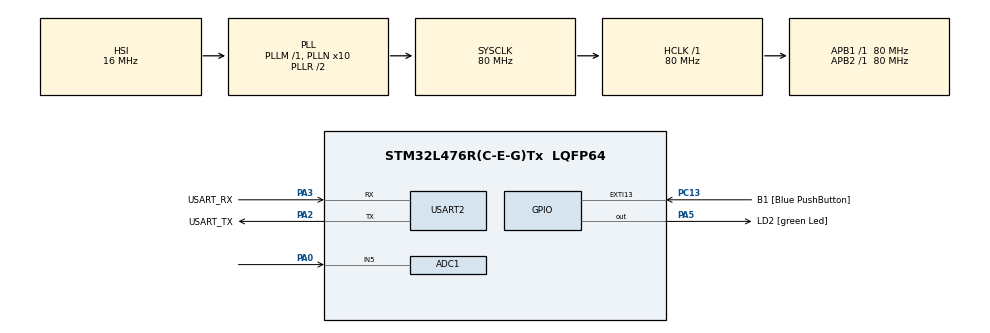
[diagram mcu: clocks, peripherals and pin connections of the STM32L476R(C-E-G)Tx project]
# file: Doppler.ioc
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ADC1.Channel-0\#ChannelRegularConversion=ADC_CHANNEL_5
ADC1.ContinuousConvMode=ENABLE
ADC1.DMAContinuousRequests=ENABLE
ADC1.NbrOfConversionFlag=1
ADC1.OffsetNumber-0\#ChannelRegularConversion=ADC_OFFSET_NONE
ADC1.Rank-0\#ChannelRegularConversion=1
ADC1.SamplingTime-0\#ChannelRegularConversion=ADC_SAMPLETIME_2CYCLES_5
ADC1.master=1
Dma.ADC1.0.Direction=DMA_PERIPH_TO_MEMORY
Dma.ADC1.0.Instance=DMA1_Channel1
Dma.ADC1.0.MemDataAlignment=DMA_MDATAALIGN_WORD
Dma.ADC1.0.MemInc=DMA_MINC_ENABLE
Dma.ADC1.0.Mode=DMA_CIRCULAR
Dma.ADC1.0.PeriphDataAlignment=DMA_PDATAALIGN_WORD
Dma.ADC1.0.PeriphInc=DMA_PINC_DISABLE
Dma.ADC1.0.Priority=DMA_PRIORITY_LOW
Dma.Request0=ADC1
Mcu.Family=STM32L4
Mcu.Name=STM32L476R(C-E-G)Tx
Mcu.Package=LQFP64
NVIC.DMA1_Channel1_IRQn=true\:0\:0\:false\:false\:true\:false\:true
NVIC.PriorityGroup=NVIC_PRIORITYGROUP_4
PA0.Signal=ADCx_IN5
PA13\ (JTMS-SWDIO).GPIO_Label=TMS
PA13\ (JTMS-SWDIO).Mode=Serial_Wire
PA13\ (JTMS-SWDIO).Signal=SYS_JTMS-SWDIO
PA14\ (JTCK-SWCLK).GPIO_Label=TCK
PA14\ (JTCK-SWCLK).Mode=Serial_Wire
PA14\ (JTCK-SWCLK).Signal=SYS_JTCK-SWCLK
PA2.GPIO_Label=USART_TX
PA2.GPIO_Mode=GPIO_MODE_AF_PP
PA2.GPIO_PuPd=GPIO_NOPULL
PA2.GPIO_Speed=GPIO_SPEED_FREQ_VERY_HIGH
PA2.Mode=Asynchronous
PA2.Signal=USART2_TX
PA3.GPIO_Label=USART_RX
PA3.GPIO_Mode=GPIO_MODE_AF_PP
PA3.GPIO_PuPd=GPIO_NOPULL
PA3.GPIO_Speed=GPIO_SPEED_FREQ_VERY_HIGH
PA3.Mode=Asynchronous
PA3.Signal=USART2_RX
PA5.GPIO_Label=LD2 [green Led]
PA5.GPIO_ModeDefaultOutputPP=GPIO_MODE_OUTPUT_PP
PA5.GPIO_PuPd=GPIO_NOPULL
PA5.GPIO_Speed=GPIO_SPEED_FREQ_LOW
PA5.Signal=GPIO_Output
PB3\ (JTDO-TRACESWO).GPIO_Label=SWO
PB3\ (JTDO-TRACESWO).Signal=SYS_JTDO-SWO
PC13.GPIO_Label=B1 [Blue PushButton]
PC13.GPIO_ModeDefaultEXTI=GPIO_MODE_IT_FALLING
PC13.GPIO_PuPd=GPIO_NOPULL
PC13.Signal=GPXTI13
PC14-OSC32_IN\ (PC14).Mode=LSE-External-Oscillator
PC14-OSC32_IN\ (PC14).Signal=RCC_OSC32_IN
PC15-OSC32_OUT\ (PC15).Mode=LSE-External-Oscillator
PC15-OSC32_OUT\ (PC15).Signal=RCC_OSC32_OUT
PH0-OSC_IN\ (PH0).Signal=RCC_OSC_IN
PH1-OSC_OUT\ (PH1).Signal=RCC_OSC_OUT
ProjectManager.HeapSize=0x200
ProjectManager.StackSize=0x400
ProjectManager.TargetToolchain=STM32CubeIDE
RCC.ADCFreq_Value=80000000
RCC.AHBFreq_Value=80000000
RCC.APB1Freq_Value=80000000
RCC.APB1TimFreq_Value=80000000
RCC.APB2Freq_Value=80000000
RCC.APB2TimFreq_Value=80000000
RCC.CortexFreq_Value=80000000
RCC.HCLKFreq_Value=80000000
RCC.HSE_VALUE=8000000
RCC.HSI_VALUE=16000000
RCC.MSI_VALUE=4000000
RCC.PLLN=10
RCC.PLLSAI1N=10
RCC.PLLSourceVirtual=RCC_PLLSOURCE_HSI
RCC.PREFETCH_ENABLE=1
RCC.SYSCLKFreq_VALUE=80000000
RCC.SYSCLKSource=RCC_SYSCLKSOURCE_PLLCLK
RCC.USBFreq_Value=80000000
RCC.VCOOutputFreq_Value=160000000
SH.ADCx_IN5.0=ADC1_IN5,IN5-Single-Ended
USART2.VirtualMode-Asynchronous=VM_ASYNC
board=NUCLEO-L476RG

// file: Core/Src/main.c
/* USER CODE BEGIN Header */
/**
 ******************************************************************************
 * @file           : main.c
 * @brief          : Main program body
 ******************************************************************************
 * @attention
 *
 * Copyright (c) 2023 STMicroelectronics.
 * All rights reserved.
 *
 * This software is licensed under terms that can be found in the LICENSE file
 * in the root directory of this software component.
 * If no LICENSE file comes with this software, it is provided AS-IS.
 *
 ******************************************************************************
 */
/* USER CODE END Header */
#include "main.h"

/* USER CODE BEGIN PD */

#define ADC_BUF_LEN 64
#define NChirp 64
#define ARM_MATH_CM4
#include "arm_math.h"
#include "arm_const_structs.h"
#include <stdio.h>

/* USER CODE END PD */

ADC_HandleTypeDef hadc1;
DMA_HandleTypeDef hdma_adc1;

UART_HandleTypeDef huart2;

/* USER CODE BEGIN PV */
volatile uint32_t adc_buf[ADC_BUF_LEN];
uint8_t Rx[1];

//
float fftIn[NChirp][ADC_BUF_LEN] = {
		{-2.5863e-07,0.00022521,-6.1129e-05,-0.00042889,-0.00063372,-0.00045172,0.00013064,0.0008364,0.00119,0.0008174,-0.00025078,-0.0014703,-0.002018,-0.0013331,0.00043194,0.0023155,0.0030704,0.0019489,-0.00066425,-0.0032882,-0.0041969,-0.0025598,0.00091116,0.0041832,0.0051644,0.0030204,-0.0011172,-0.004791,-0.0056927,-0.0031999,0.0012233,0.0049247,0.0056551,0.0030479,-0.001215,-0.0045326,-0.0050234,-0.0026021,0.0010731,0.0037453,0.0040073,0.0019829,-0.00084314,-0.0027672,-0.0028584,-0.0013587,0.00058805,0.0018357,0.001823,0.00083689,-0.00036713,-0.0010808,-0.0010406,-0.00045826,0.00020521,0.00056895,0.00052664,0.00022396,-9.8551e-05,-0.00026398,-0.0002363,-9.7033e-05,4.2643e-05,0.00010846},
		{-0.00011764,0.00017898,-0.00012513,-0.00047058,-0.00061149,-0.00035661,0.00025963,0.00091687,0.0011498,0.00063762,-0.00048411,-0.0016101,-0.0019384,-0.0010327,0.00081133,0.0025388,0.0029488,0.0014906,-0.0012138,-0.0035901,-0.0040229,-0.0019375,0.0016406,0.0045702,0.0049261,0.0022686,-0.0019787,-0.0052254,-0.0054236,-0.0023714,0.0021407,0.0053636,0.0053681,0.0022153,-0.0020766,-0.0049407,-0.004754,-0.0018683,0.0018137,0.0040752,0.0037649,0.0014075,-0.0014045,-0.0030077,-0.0026904,-0.00095257,0.0009798,0.0019907,0.0017101,0.00056679,-0.00060818,-0.0011744,-0.00097145,-0.00030637,0.00033652,0.00061764,0.00048979,0.00014542,-0.00016397,-0.0002872,-0.00021905,-6.1308e-05,7.1105e-05,0.00011804},
		{-0.00011015,0.00012903,-0.00018696,-0.00050252,-0.00057733,-0.00025347,0.00038414,0.00097933,0.00108,0.00044542,-0.00070618,-0.0017144,-0.0018181,-0.00070909,0.0011718,0.0026935,0.0027551,0.0010004,-0.0017455,-0.0038164,-0.0037456,-0.0012702,0.0023226,0.0048377,0.0045724,0.0014384,-0.0027793,-0.0055311,-0.0050245,-0.0014667,0.0029902,0.005658,0.0049447,0.001341,-0.0028798,-0.0051995,-0.0043644,-0.0010868,0.0024958,0.0042915,0.0034592,0.00078945,-0.0019363,-0.0031625,-0.0024403,-0.00050635,0.001338,0.0020875,0.001543,0.00028796,-0.00083399,-0.0012298,-0.00086914,-0.00014463,0.00045778,0.00064511,0.00043627,6.2856e-05,-0.00022415,-0.00029998,-0.00019372,-2.3393e-05,9.7596e-05,0.00012337},
		{-9.92e-05,7.6607e-05,-0.00024468,-0.00052442,-0.00053041,-0.00014508,0.00049937,0.0010169,0.00098916,0.00024342,-0.00091329,-0.0017758,-0.0016577,-0.00036211,0.0015022,0.0027943,0.002495,0.0004859,-0.0022199,-0.003941,-0.0033737,-0.0005738,0.0029427,0.0049939,0.004107,0.00059834,-0.0035146,-0.0056881,-0.0044787,-0.00054511,0.0037633,0.0058141,0.0043908,0.00041797,-0.0036197,-0.0053378,-0.0038509,-0.00028325,0.003115,0.0043794,0.0030248,0.00014219,-0.0023996,-0.0032272,-0.0021203,-4.6644e-05,0.0016624,0.0021263,0.0013323,-4.6784e-07,-0.0010256,-0.0012479,-0.00074569,2.0258e-05,0.00056583,0.00065152,0.00036944,-2.2081e-05,-0.00027703,-0.00030263,-0.00016118,1.4961e-05,0.00011988,0.00012391},
		{-8.4359e-05,2.23e-05,-0.00029649,-0.0005328,-0.00047058,-3.2248e-05,0.00060187,0.0010348,0.00087304,3.4527e-05,-0.0010975,-0.0018014,-0.0014553,-1.6385e-05,0.0017993,0.0028204,0.0021772,-3.6639e-05,-0.0026446,-0.0039727,-0.0029309,0.00013209,0.0034981,0.0050195,0.0035394,-0.00026208,-0.0041576,-0.005698,-0.0038353,0.00039655,0.0044361,0.0058185,0.0037253,-0.00050346,-0.0042427,-0.0053136,-0.0032384,0.00052693,0.003643,0.00435,0.00251,-0.0004978,-0.0028044,-0.0031967,-0.0017452,0.00040588,0.001932,0.0020939,0.0010796,-0.00029385,-0.0011875,-0.0012224,-0.00059551,0.00018867,0.00065455,0.00063775,0.00028787,-0.00010599,-0.00031898,-0.00029359,-0.00012337,5.313e-05,0.00013884,0.00011955},
		{-6.5572e-05,-3.1863e-05,-0.00034209,-0.00053086,-0.000402,7.9428e-05,0.00069079,0.0010252,0.00073898,-0.00017405,-0.001256,-0.0017828,-0.001222,0.00033221,0.0020497,0.0027875,0.0018099,-0.00056247,-0.0030129,-0.0039113,-0.0024137,0.00083755,0.0039664,0.0049229,0.002882,-0.001115,-0.00469,-0.0055654,-0.0030809,0.0013382,0.0049834,0.0056567,0.0029595,-0.0014233,-0.0047577,-0.0051481,-0.0025347,0.0013387,0.0040709,0.0042089,0.001939,-0.0011333,-0.0031284,-0.0030741,-0.0013213,0.00084896,0.00215,0.0020109,0.00079753,-0.00057447,-0.0013167,-0.0011666,-0.00042489,0.00034683,0.00072088,0.00060358,0.00019934,-0.0001875,-0.00035078,-0.00027612,-8.0629e-05,8.9955e-05,0.00015186,0.00011122},
		{-4.4987e-05,-8.5288e-05,-0.0003804,-0.00051694,-0.00032427,0.00019075,0.00076559,0.00099663,0.00058786,-0.00037903,-0.0013862,-0.0017235,-0.0009579,0.00067438,0.0022557,0.0026799,0.0014059,-0.001074,-0.0032934,-0.0037526,-0.0018382,0.0015231,0.0043342,0.0047063,0.0021646,-0.0019459,-0.005115,-0.0053009,-0.0022516,0.0022269,0.0054254,0.005367,0.0021134,-0.0022899,-0.0051627,-0.0048601,-0.0017598,0.0021051,0.004393,0.003936,0.001301,-0.0017265,-0.0033636,-0.0028611,-0.00085162,0.0012767,0.0022989,0.0018538,0.00048841,-0.0008426,-0.0014067,-0.0010709,-0.00024265,0.0004974,0.00076548,0.00054889,0.00010253,-0.00026251,-0.00037339,-0.00024879,-3.5161e-05,0.00012378,0.00016007,9.8307e-05},
		{-2.1865e-05,-0.00013698,-0.00040915,-0.0004919,-0.00023925,0.00029632,0.00082171,0.00094304,0.00042352,-0.00057465,-0.0014811,-0.001623,-0.00067552,0.00099553,0.0024036,0.0025186,0.00096431,-0.0015571,-0.0035087,-0.0034954,-0.0012211,0.0021654,0.004594,0.0043704,0.0013804,-0.0027198,-0.0054034,-0.0048994,-0.0013702,0.0030761,0.0057027,0.0049278,0.0012201,-0.0030982,-0.005399,-0.0044217,-0.00094545,0.0028024,0.0045966,0.0035692,0.00062846,-0.0022819,-0.0035016,-0.0025699,-0.00036219,0.0016607,0.0023817,0.0016455,0.00016443,-0.0010844,-0.001453,-0.00094278,-4.838e-05,0.00063287,0.00078912,0.00047523,4.2891e-07,-0.00033019,-0.00038034,-0.00021138,1.3107e-05,0.00015343,0.00016162,8.131e-05},
		{2.5976e-06,-0.00018533,-0.00042974,-0.00045539,-0.00014879,0.0003948,0.00085945,0.00086907,0.00024991,-0.00075517,-0.0015474,-0.0014898,-0.00037666,0.0012954,0.0024995,0.002291,0.00049326,-0.0019995,-0.0036346,-0.0031673,-0.00056768,0.0027579,0.0047405,0.0039255,0.00056304,-0.0034256,-0.0055488,-0.0043679,-0.00045365,0.0038299,0.0058449,0.0043541,0.00028945,-0.0038303,-0.0055208,-0.0038754,-0.00010485,0.0034312,0.0046734,0.0030948,-5.3815e-05,-0.0027742,-0.0035386,-0.0021995,0.00014857,0.0020009,0.0024009,0.0013922,-0.00016733,-0.0012943,-0.0014508,-0.00078229,0.00014514,0.0007494,0.00078475,0.00038693,-0.00010222,-0.00038643,-0.00037551,-0.0001665,6.1599e-05,0.00017796,0.00015889,6.1764e-05},
		{2.745e-05,-0.00022983,-0.0004403,-0.00040934,-5.5938e-05,0.00048496,0.00087769,0.00077467,7.1141e-05,-0.00091841,-0.0015737,-0.0013146,-6.8944e-05,0.0015629,0.0025373,0.0020112,2.1297e-05,-0.0023869,-0.0036732,-0.0027617,9.1685e-05,0.0032825,0.0047617,0.003381,-0.00027012,-0.0040506,-0.0055765,-0.0037289,0.00047327,0.0044867,0.0058374,0.0036755,-0.00064068,-0.0044545,-0.0054862,-0.0032368,0.00075557,0.0039776,0.0046115,0.0025405,-0.00075482,-0.0031797,-0.00348,-0.0017694,0.00064549,0.0022885,0.0023483,0.0010957,-0.00049918,-0.0014666,-0.0014088,-0.0005941,0.00033613,0.00084425,0.00075397,0.00028288,-0.00020324,-0.00043317,-0.0003578,-0.00011554,0.00010826,0.00019736,0.00014964,3.9021e-05},
		{5.1718e-05,-0.00026892,-0.00044147,-0.00035466,3.855e-05,0.00056291,0.00087732,0.00066379,-0.00010632,-0.0010619,-0.0015677,-0.001118,0.00023888,0.0017963,0.0025132,0.0016842,-0.00045753,-0.0027306,-0.0036219,-0.0022871,0.00074457,0.0037252,0.0046783,0.0027627,-0.0010879,-0.0045639,-0.0054402,-0.002997,0.0013832,0.005031,0.0056805,0.0028939,-0.0015707,-0.0049696,-0.0052956,-0.00249,0.0015767,0.0044137,0.0044329,0.001908,-0.0014224,-0.0035093,-0.0033213,-0.0012861,0.0011363,0.0025033,0.0022229,0.00075869,-0.00081677,-0.0015982,-0.0013229,-0.00038806,0.00052174,0.00091149,0.00070155,0.00016921,-0.00029905,-0.00046394,-0.00032895,-5.8921e-05,0.00015162,0.00020978,0.00013485,1.3939e-05},
		{7.5069e-05,-0.00030207,-0.00043396,-0.00029179,0.00013147,0.00063024,0.0008564,0.00053916,-0.00028364,-0.0011792,-0.0015209,-0.00089354,0.00054236,0.0019839,0.0024278,0.0013208,-0.0009202,-0.0030034,-0.0034791,-0.0017489,0.0013959,0.0040818,0.0044769,0.0020763,-0.0018779,-0.0049787,-0.0051686,-0.002184,0.0022759,0.0054483,0.0053599,0.0020355,-0.0024522,-0.0053551,-0.004974,-0.0016842,0.002371,0.0047338,0.0041289,0.0012223,-0.0020515,-0.0037393,-0.0030662,-0.00075935,0.0015968,0.0026486,0.0020278,0.00040187,-0.0011099,-0.001681,-0.0011996,-0.00017203,0.0006919,0.00095168,0.00062372,4.9869e-05,-0.0003863,-0.00048115,-0.00028704,1.7882e-07,0.00019256,0.00021644,0.00011529,-1.2205e-05},
		{9.6483e-05,-0.00032901,-0.00041589,-0.00022376,0.0002218,0.00068225,0.00081756,0.00040243,-0.00045272,-0.0012705,-0.0014437,-0.00064855,0.00083013,0.0021292,0.0022884,0.00092671,-0.0013606,-0.0031989,-0.003262,-0.0011806,0.0019936,0.0043238,0.0041672,0.001328,-0.0026201,-0.0052592,-0.0047807,-0.0013137,0.003097,0.0057367,0.0049066,0.0011219,-0.0032848,-0.0056054,-0.0045098,-0.00082013,0.0031132,0.0049182,0.0037118,0.00049064,-0.0026448,-0.0038676,-0.00272,-0.00021152,0.0020126,0.0027281,0.0017836,2.91e-05,-0.0013789,-0.0017167,-0.0010318,5.9507e-05,0.0008431,0.00096625,0.00052681,-7.5191e-05,-0.00046325,-0.00048322,-0.00023422,6.0965e-05,0.00022733,0.00021433,9.0781e-05,-3.8583e-05},
		{0.00011496,-0.00034883,-0.00038855,-0.00014905,0.00030676,0.00071984,0.00075899,0.00025588,-0.0006137,-0.0013321,-0.0013316,-0.00038699,0.0011003,0.0022238,0.0020972,0.00051196,-0.0017654,-0.0033271,-0.0029634,-0.00058109,0.0025553,0.0044681,0.0037519,0.00054944,-0.0033137,-0.0054078,-0.0042454,-0.00042156,0.0038484,0.0058599,0.0043297,0.00019292,-0.0040113,-0.0056931,-0.0039331,5.5395e-05,0.0037571,0.0049737,0.003191,-0.00024307,-0.003161,-0.0038874,-0.0023026,0.00034388,0.0023824,0.0027198,0.0014769,-0.00035322,-0.0016047,-0.0016989,-0.00083034,0.00028706,0.00097102,0.00094723,0.00041008,-0.00019995,-0.0005265,-0.00046987,-0.00017457,0.00012129,0.00025537,0.00020532,6.1767e-05,-6.4333e-05},
		{0.00013033,-0.00036039,-0.00035343,-7.1841e-05,0.00038439,0.00074062,0.0006841,0.00010409,-0.0007596,-0.0013654,-0.0011883,-0.00011632,0.0013427,0.0022647,0.0018543,7.9275e-05,-0.0021353,-0.0033759,-0.0025899,3.0714e-05,0.003057,0.0045077,0.0032449,-0.00023792,-0.0039112,-0.0054143,-0.0036371,0.00050191,0.0044996,0.0058382,0.0036417,-0.00076267,-0.0046447,-0.0056439,-0.0032577,0.00094633,0.0043175,0.004888,0.0025757,-0.00098712,-0.0035798,-0.0038009,-0.0018185,0.00089812,0.0026777,0.002636,0.0011246,-0.00072798,-0.0017901,-0.0016326,-0.00060296,0.00051025,0.0010735,0.00089914,0.00027884,-0.00032433,-0.00057426,-0.00043976,-0.00010712,0.00017967,0.00027552,0.00019051,3.0763e-05,-8.9457e-05},
		{0.00014164,-0.00036448,-0.00031035,5.7175e-06,0.00045445,0.00074318,0.00059448,-4.9037e-05,-0.00088692,-0.0013662,-0.0010222,0.00015345,0.0015559,0.0022513,0.0015704,-0.00035514,-0.0024528,-0.0033369,-0.0021584,0.00064311,0.0034662,0.0044318,0.0026559,-0.0010146,-0.0044067,-0.0052929,-0.0029168,0.0014077,0.0050349,0.0056695,0.0028465,-0.0017028,-0.0051633,-0.0054496,-0.0024685,0.0018022,0.0047449,0.0046796,0.0018951,-0.0017007,-0.0039205,-0.0035947,-0.0012718,0.0014426,0.0028988,0.0024752,0.00073032,-0.001082,-0.0019216,-0.0015163,-0.00035949,0.0007257,0.0011405,0.00082399,0.00013755,-0.00043574,-0.00060655,-0.00039608,-3.4306e-05,0.00023383,0.00028731,0.0001674,-2.8903e-06,-0.00011196},
		{0.00014879,-0.00036059,-0.00026135,8.4097e-05,0.00051374,0.00073114,0.00049131,-0.00020229,-0.00099468,-0.0013355,-0.00082588,0.00042131,0.001731,0.0021881,0.0012501,-0.00076687,-0.0027079,-0.00322,-0.0016737,0.0012444,0.003807,0.0042532,0.0020102,-0.0017794,-0.0048061,-0.0050384,-0.0021207,0.0022643,0.0054497,0.00537,0.0019873,-0.0025811,-0.0055472,-0.0050893,-0.0016381,0.0026279,0.0050558,0.0043447,0.001156,-0.0023795,-0.0041463,-0.0033015,-0.00068255,0.0019353,0.0030403,0.0022402,0.0003175,-0.0014086,-0.0020063,-0.0013505,-9.3756e-05,0.0009194,0.0011779,0.00072199,-1.4095e-05,-0.00053761,-0.00062046,-0.00033803,4.2828e-05,0.00028223,0.00029065,0.00013852,-3.8372e-05,-0.00013227},
		{0.00015106,-0.00034863,-0.00020558,0.00015983,0.00056033,0.00070357,0.00037806,-0.00034948,-0.0010798,-0.0012748,-0.00061717,0.00067853,0.001865,0.002074,0.00089754,-0.001172,-0.0029003,-0.0030279,-0.0011483,0.0018172,0.0040493,0.003966,0.0013007,-0.0024963,-0.0050737,-0.0046615,-0.0012849,0.0030874,0.0057107,0.0049023,0.0010732,-0.0034105,-0.0057755,-0.0046166,-0.00074281,0.0033805,0.005235,0.0038848,0.00036691,-0.0029961,-0.0042624,-0.0029064,-7.6104e-05,0.0023851,0.0031029,0.0019398,-0.00011399,-0.0017045,-0.0020265,-0.001143,0.00017573,0.0010928,0.0011823,0.00059285,-0.00016444,-0.00062631,-0.00061336,-0.00026741,0.00012079,0.00032223,0.00028404,0.00010362,-7.2786e-05,-0.00014881},
		{0.00014801,-0.00032887,-0.00014595,0.00023233,0.00059559,0.00065787,0.00025516,-0.00048898,-0.0011398,-0.0011831,-0.00039456,0.00091972,0.0019602,0.0019066,0.00052666,-0.0015492,-0.0030251,-0.0027617,-0.00059861,0.002338,0.0041974,0.0035779,0.0005674,-0.0031475,-0.0052293,-0.0041675,-0.00039604,0.0038186,0.0058491,0.0043186,0.00012632,-0.0041566,-0.0058649,-0.0040054,0.00017689,0.0040464,0.005281,0.0033187,-0.00041822,-0.003543,-0.0042611,-0.0024355,0.00054784,0.0027741,0.0030819,0.0015799,-0.00054388,-0.0019582,-0.0019886,-0.00090121,0.00044776,0.0012338,0.0011467,0.00044635,-0.00031663,-0.00070027,-0.00058921,-0.00018801,0.00019704,0.00035487,0.00026843,6.4099e-05,-0.00010672,-0.00016079},
		{0.00014078,-0.00030262,-8.3354e-05,0.00029917,0.00061724,0.00060054,0.00012704,-0.00061723,-0.0011736,-0.0010677,-0.00015653,0.0011397,0.0020051,0.001699,0.00014304,-0.0018883,-0.0030788,-0.0024333,-3.2595e-05,0.0028036,0.0042387,0.0031062,-0.00018362,-0.0037252,-0.0052436,-0.0035562,0.0004956,0.004459,0.0058261,0.0036243,-0.00082849,-0.0047846,-0.005798,-0.0032916,0.0010984,0.0046034,0.0051812,0.0026585,-0.0012111,-0.003987,-0.0041446,-0.0018851,0.001158,0.0030964,0.0029704,0.0011716,-0.00096232,-0.0021571,-0.0018978,-0.00062579,0.00071052,0.0013432,0.0010804,0.00028283,-0.0004632,-0.00075126,-0.0005464,-9.7915e-05,0.00026997,0.00037675,0.0002444,2.1444e-05,-0.00013913,-0.00016859},
		{0.00012807,-0.00026988,-1.8875e-05,0.00035992,0.00062563,0.00052898,-3.0763e-06,-0.00073036,-0.0011805,-0.00092472,7.7966e-05,0.0013295,0.0020049,0.0014563,-0.00024551,-0.0021805,-0.0030579,-0.0020455,0.00052894,0.0032011,0.0041779,0.0025579,-0.00093485,-0.0042208,-0.0051403,-0.0028645,0.0013836,0.004998,0.0056602,0.0028415,-0.0017699,-0.0053052,-0.0055848,-0.0024927,0.0019956,0.00506,0.0049461,0.0019131,-0.0019798,-0.0043371,-0.0039174,-0.0012813,0.0017378,0.0033323,0.0027644,0.00072467,-0.0013721,-0.0022941,-0.0017461,-0.00032949,0.00095898,0.0014174,0.00097752,0.00010526,-0.00059937,-0.00078307,-0.00048333,-4.0204e-06,0.00033477,0.00038767,0.00021131,-2.4077e-05,-0.00016778,-0.00017124},
		{0.0001111,-0.00023084,4.6073e-05,0.00041156,0.00061929,0.00044419,-0.0001335,-0.0008277,-0.0011618,-0.00076547,0.00031309,0.0014936,0.00196,0.001174,-0.00062499,-0.002421,-0.0029609,-0.0016079,0.0010824,0.0035225,0.0040166,0.0019526,-0.0016561,-0.0046067,-0.004893,-0.0020976,0.0022313,0.0053971,0.0053478,0.0019714,-0.0026617,-0.005683,-0.0052212,-0.0016095,0.0028446,0.0053845,0.0045796,0.0011224,-0.0026942,-0.0045684,-0.0035755,-0.0006221,0.0022911,0.0034759,0.0024897,0.00024684,-0.0017405,-0.0023673,-0.0015405,-1.4915e-05,0.0011842,0.0014484,0.00084497,-8.0398e-05,-0.00072185,-0.00079261,-0.00040757,9.2938e-05,0.00039398,0.00038719,0.00017057,-6.9876e-05,-0.00019311,-0.0001686},
		{8.9581e-05,-0.00018727,0.00010947,0.00045468,0.00059994,0.0003515,-0.00025935,-0.00090723,-0.0011161,-0.00058528,0.00053965,0.0016228,0.0018655,0.0008658,-0.00099241,-0.0026079,-0.0027961,-0.001134,0.0016113,0.0037626,0.0037644,0.0012925,-0.0023368,-0.004877,-0.0045388,-0.0012759,0.0030237,0.0056709,0.0048882,0.0010544,-0.003494,-0.0059236,-0.0047258,-0.00068242,0.0036102,0.005553,0.0040742,0.00028364,-0.0033503,-0.0046832,-0.0031329,4.5313e-05,0.0027756,0.0035234,0.0021424,-0.00024605,-0.0020705,-0.0023831,-0.0012867,0.00030479,0.0013821,0.0014417,0.00068243,-0.0002673,-0.00082683,-0.00077734,-0.00031366,0.00019038,0.00044204,0.00037475,0.00012269,-0.00011642,-0.00021277,-0.00016082},
		{6.4215e-05,-0.00013954,0.00017033,0.00048795,0.00056735,0.00025008,-0.00037976,-0.00096496,-0.0010473,-0.00039349,0.000753,0.001713,0.0017297,0.00053597,-0.0013319,-0.0027332,-0.0025689,-0.0006325,0.0021039,0.0039059,0.0034144,0.00059747,-0.0029668,-0.0050285,-0.0040555,-0.00041658,0.0037441,0.0057971,0.0043129,0.00010366,-0.0042446,-0.006009,-0.0041027,0.00025775,0.0043044,0.0055859,0.003464,-0.00056934,-0.0039281,-0.0046644,-0.0025976,0.00072593,0.0031944,0.0034775,0.0017173,-0.00073972,-0.0023452,-0.0023251,-0.00099779,0.00061969,0.0015427,0.0013899,0.00049906,-0.00045198,-0.00091112,-0.00074094,-0.00020934,0.00028742,0.00048065,0.0003511,6.9434e-05,-0.00016099,-0.00022738,-0.00014761},
		{3.5558e-05,-8.871e-05,0.0002274,0.00050953,0.00052268,0.00014353,-0.00049311,-0.00099996,-0.0009528,-0.00019245,0.00095081,0.0017614,0.0015557,0.00020153,-0.0016413,-0.002787,-0.0022766,-0.00011215,0.0025405,0.0039651,0.0029772,-0.00011189,-0.0035246,-0.0050515,-0.0034823,0.00044666,0.0043807,0.0057909,0.0036297,-0.0008509,-0.0048874,-0.0059464,-0.003366,0.0012081,0.0048938,0.0054664,0.0027489,-0.0014094,-0.0043901,-0.0045172,-0.0019862,0.0014004,0.0035372,0.003338,0.0012458,-0.0012212,-0.0025604,-0.0022055,-0.0006674,0.00092877,0.0016628,0.0012992,0.00029448,-0.00062754,-0.00096626,-0.00068066,-9.5352e-05,0.00037733,0.00050393,0.00031555,1.2604e-05,-0.00020161,-0.0002353,-0.00012957},
		{4.7465e-06,-3.6672e-05,0.00027958,0.00052043,0.00046538,3.515e-05,-0.0005924,-0.001011,-0.00083617,1.2379e-05,0.0011266,0.0017739,0.0013434,-0.00014616,-0.0019148,-0.002777,-0.0019298,0.00040568,0.0029249,0.0039147,0.0024707,-0.00081284,-0.0039924,-0.0049589,-0.0028153,0.0012987,0.004919,0.0056176,0.0028436,-0.0017868,-0.0054147,-0.0057191,-0.0025326,0.0021331,0.0053568,0.0052159,0.0019768,-0.0022165,-0.0047619,-0.0042621,-0.0013165,0.0020427,0.0037937,0.0031052,0.00073287,-0.001673,-0.0027076,-0.0020174,-0.00031828,0.0012157,0.0017387,0.0011683,7.8854e-05,-0.00079143,-0.00099995,-0.00059911,2.4603e-05,0.00045952,0.00051517,0.00027094,-4.7688e-05,-0.00023899,-0.00023763,-0.00010672},
		{-2.7589e-05,1.6694e-05,0.00032533,0.00051975,0.00039852,-7.5884e-05,-0.00068012,-0.0010048,-0.00070074,0.00021386,0.001273,0.0017388,0.0011024,-0.00048477,-0.0021402,-0.0027057,-0.0015436,0.00091788,0.0032292,0.0037806,0.0019098,-0.0015004,-0.0043719,-0.0047366,-0.0020839,0.0021338,0.0053123,0.0053204,0.0019842,-0.0026872,-0.0057933,-0.0053525,-0.0016406,0.0030014,0.0056828,0.0048087,0.0011238,-0.0029882,-0.0049861,-0.0038685,-0.00060046,0.0026481,0.0039394,0.0027762,0.00019131,-0.0020925,-0.0027885,-0.0017737,5.5129e-05,0.0014773,0.0017653,0.0010002,-0.00015138,-0.00093644,-0.0010038,-0.00049717,0.00014806,0.00053183,0.00051068,0.00021572,-0.00010858,-0.00026983,-0.00023237,-7.9635e-05},
		{-6.0453e-05,6.9346e-05,0.0003643,0.00050799,0.00032341,-0.000183,-0.00075193,-0.00097205,-0.00055072,0.00041619,0.0013917,0.0016666,0.00083362,-0.00081516,-0.0023154,-0.0025719,-0.0011098,0.0014104,0.0034581,0.0035502,0.0012953,-0.002153,-0.0046385,-0.004403,-0.0012913,0.0029277,0.005591,0.0048835,0.0010815,-0.0035184,-0.0060329,-0.0048406,-0.00068729,0.0038086,0.0058527,0.0042869,0.0002307,-0.0036803,-0.0051024,-0.0033809,0.00014591,0.0031779,0.0039856,0.0023718,-0.0003667,-0.0024592,-0.0027887,-0.0014705,0.00042942,0.0017028,0.0017484,0.00079964,-0.0003767,-0.0010624,-0.00098143,-0.0003773,0.00027228,0.00059223,0.00049169,0.00015117,-0.00016867,-0.00029575,-0.00021969,-4.9146e-05},
		{-9.3183e-05,0.00012061,0.00039408,0.00048498,0.00024067,-0.0002873,-0.00080706,-0.00091774,-0.00039044,0.00060286,0.0014809,0.0015569,0.00054853,-0.0011255,-0.0024384,-0.0023746,-0.00065445,0.0018633,0.00361,0.0032392,0.00063813,-0.0027507,-0.0047946,-0.0039528,-0.00046121,0.0036313,0.0057189,0.0043093,0.00011831,-0.0042839,-0.0061268,-0.0041987,0.00029684,0.0045253,0.0058885,0.0036312,-0.00066288,-0.0042845,-0.0050737,-0.0027935,0.00089207,0.0036441,0.0039178,0.0018903,-0.00093023,-0.0027693,-0.0027134,-0.0011204,0.00080722,0.0018879,0.0016794,0.00057444,-0.00060133,-0.0011572,-0.00092951,-0.00024331,0.00039438,0.0006341,0.00045711,8.0529e-05,-0.00022639,-0.00031251,-0.00020053,-1.5819e-05},
		{-0.00012533,0.00016881,0.00041602,0.000451,0.00015255,-0.00038469,-0.0008436,-0.00084195,-0.00021768,0.00078075,0.0015326,0.0014134,0.00024877,-0.0014072,-0.0025031,-0.0021196,-0.00018778,0.0022781,0.003672,0.0028439,-2.0947e-05,-0.0032882,-0.004834,-0.0034156,0.0003772,0.0042557,0.0057139,0.0036281,-0.0008316,-0.0049376,-0.0060669,-0.0034518,0.0012737,0.0051214,0.0057569,0.0028913,-0.0015529,-0.0047836,-0.0049123,-0.002126,0.0016243,0.0039973,0.0037501,0.0013624,-0.001469,-0.0030066,-0.0025558,-0.00073134,0.0011637,0.0020253,0.0015613,0.00032112,-0.00081268,-0.0012239,-0.00084819,-9.862e-05,0.00050527,0.00066375,0.00040958,5.2009e-06,-0.00027944,-0.00032294,-0.00017514,1.9299e-05},
		{-0.0001549,0.00021322,0.0004288,0.00040778,6.2408e-05,-0.00047175,-0.00086144,-0.00075023,-4.4789e-05,0.00093773,0.0015509,0.001235,-5.5491e-05,-0.0016596,-0.0025122,-0.0018196,0.00028916,0.0026374,0.0036439,0.0023862,-0.00067742,-0.0037489,-0.0047585,-0.0027847,0.0012033,0.0047739,0.0055617,0.0028723,-0.001765,-0.0054576,-0.0058352,-0.0026066,0.0022206,0.0056037,0.0054821,0.0020645,-0.002429,-0.0051651,-0.0046187,-0.0013893,0.0023311,0.0042719,0.0034728,0.00076895,-0.0019816,-0.0031657,-0.0023367,-0.0003212,0.0014976,0.0021109,0.0013973,5.6596e-05,-0.0010116,-0.0012586,-0.00074356,5.3547e-05,0.00060786,0.00067435,0.00034856,-7.2294e-05,-0.00032728,-0.00032355,-0.00014342,5.5647e-05},
		{-0.00018082,0.00025263,0.00043215,0.00035473,-3.0153e-05,-0.00054964,-0.00085932,-0.00064072,0.00013367,0.0010727,0.0015349,0.0010302,-0.0003579,-0.0018695,-0.0024605,-0.0014733,0.00075358,0.0029312,0.0035362,0.0018626,-0.0013251,-0.0041107,-0.004559,-0.0020781,0.0020117,0.0051828,0.0052714,0.0020192,-0.0026737,-0.0058625,-0.0054689,-0.0016882,0.0031278,0.0059416,0.0050651,0.0011656,-0.0032299,-0.0054088,-0.0041962,-0.00061141,0.0029856,0.0044246,0.0031077,0.00016203,-0.0024497,-0.0032487,-0.002043,0.00011428,0.0018045,0.0021366,0.0011947,-0.0002174,-0.0011803,-0.0012614,-0.00061405,0.00020617,0.00069598,0.00066564,0.00027576,-0.00015056,-0.00036731,-0.00031475,-0.00010644,9.1639e-05},
		{-0.00020396,0.00028735,0.00042615,0.00029407,-0.00012182,-0.0006163,-0.00083881,-0.00051684,0.00030486,0.0011837,0.0014813,0.0008012,-0.00065045,-0.0020399,-0.0023451,-0.0010924,0.0012042,0.0031525,0.0033356,0.0013041,-0.001947,-0.0043829,-0.004251,-0.0013273,0.0027768,0.0054615,0.004855,0.0011138,-0.0035063,-0.0061064,-0.0049584,-0.0007204,0.0039497,0.006134,0.0045199,0.00022685,-0.0039631,-0.0055252,-0.0036616,0.00020023,0.0035698,0.0044615,0.002654,-0.00046761,-0.00287,-0.0032392,-0.0016862,0.00055229,0.0020621,0.0021052,0.00094919,-0.00049321,-0.0013316,-0.0012259,-0.00046229,0.00036362,0.0007707,0.0006395,0.00019404,-0.00022998,-0.00039912,-0.00029736,-6.564e-05,0.00012681},
		{-0.00022229,0.00031498,0.00041071,0.00022754,-0.00020921,-0.00066788,-0.00079905,-0.00037983,0.00047304,0.0012676,0.0013953,0.00055184,-0.00093361,-0.0021606,-0.0021819,-0.00068605,0.0016267,0.0033065,0.0030623,0.00070289,-0.0025167,-0.0045398,-0.0038381,-0.00053805,0.0034669,0.0055923,0.0043093,0.00017934,-0.0042647,-0.0061987,-0.0043142,0.00028329,0.0046913,0.0061649,0.0038339,-0.00072097,-0.0046082,-0.0054826,-0.0030342,0.0010294,0.0040734,0.0043907,0.0021092,-0.0011004,-0.003214,-0.003146,-0.001283,0.00098928,0.0022742,0.0020148,0.00067475,-0.00076271,-0.0014473,-0.0011612,-0.00029602,0.0005142,0.00082509,0.00059369,0.00010087,-0.00030428,-0.00042122,-0.00027113,-2.0427e-05,0.00015979},
		{-0.00023461,0.00033594,0.00038671,0.00015654,-0.00029283,-0.00070364,-0.00074157,-0.00023659,0.00062818,0.0013193,0.0012789,0.00029324,-0.0011895,-0.0022308,-0.0019642,-0.00026097,0.0020123,0.0033811,0.0027072,8.6224e-05,-0.0030346,-0.0045883,-0.0033327,0.00026879,0.0040831,0.0056056,0.0036545,-0.00076012,-0.0049204,-0.006136,-0.0035426,0.0012735,0.0053184,0.006031,0.003059,-0.001669,-0.0051473,-0.0053206,-0.0023067,0.0018184,0.0044783,0.0041935,0.0015084,-0.0017031,-0.0034756,-0.0029631,-0.00083278,0.0014031,0.0024299,0.0018746,0.00037265,-0.0010182,-0.0015233,-0.0010565,-0.00011386,0.00065361,0.0008568,0.00053115,3.6384e-06,-0.00037371,-0.00043284,-0.00023734,2.6071e-05,0.00018984},
		{-0.00024202,0.0003496,0.00035342,8.1709e-05,-0.00036958,-0.00072461,-0.00066758,-8.8409e-05,0.00076709,0.0013464,0.001128,2.5349e-05,-0.0014181,-0.002251,-0.0017052,0.00016694,0.0023498,0.0033694,0.0022923,-0.00053294,-0.0034724,-0.0045376,-0.0027394,0.0010671,0.0046003,0.0054721,0.0028954,-0.0016993,-0.0054504,-0.0059275,-0.0027065,0.0022514,0.0058087,0.0057606,0.0021815,-0.0025856,-0.0055523,-0.005001,-0.0014969,0.0025808,0.0047558,0.0038877,0.00085349,-0.0022901,-0.0036563,-0.0027062,-0.00035269,0.0017936,0.0025205,0.0016789,5.2022e-05,-0.0012564,-0.0015637,-0.00092547,7.504e-05,0.00078061,0.00086922,0.00045354,-9.7849e-05,-0.00043514,-0.00043289,-0.00019442,7.5241e-05,0.00021632},
		{-0.00024246,0.00035564,0.00031277,5.3733e-06,-0.00043749,-0.0007291,-0.00057958,6.2998e-05,0.00089055,0.0013421,0.00095633,-0.00024239,-0.0016153,-0.0022154,-0.0014026,0.00059054,0.002627,0.0032825,0.0018256,-0.0011443,-0.0038277,-0.0043674,-0.0020843,0.0018505,0.0050018,0.0052041,0.0020734,-0.0025873,-0.0058658,-0.0055528,-0.0017649,0.0031843,0.0061553,0.0053185,0.0012404,-0.0034391,-0.0058121,-0.0045549,-0.00065888,0.0032953,0.0049334,0.0034709,0.00015883,-0.0028201,-0.003745,-0.0023649,0.00015114,0.0021509,0.0025534,0.0014289,-0.00027721,-0.0014622,-0.0015642,-0.00076495,0.00026926,0.00089291,0.00085618,0.0003582,-0.00019933,-0.00048675,-0.00042144,-0.00014543,0.00012304,0.0002378},
		{-0.00023695,0.00035401,0.00026469,-7.1135e-05,-0.00049705,-0.00071791,-0.00047806,0.00021273,0.00099318,0.0013045,0.00076021,-0.00050498,-0.0017772,-0.0021315,-0.0010633,0.0010065,0.0028444,0.0031167,0.0013072,-0.0017248,-0.0041,-0.004091,-0.0013703,0.0025947,0.005291,0.0048037,0.0011987,-0.0034286,-0.0061258,-0.0050551,-0.00078858,0.0040334,0.0063656,0.0047535,0.00026289,-0.0042222,-0.0059369,-0.0039787,0.00021898,0.0039362,0.0049668,0.0029658,-0.00054353,-0.0032821,-0.0037331,-0.0019503,0.00065976,0.0024546,0.0025142,0.0011395,-0.00060377,-0.0016396,-0.0015215,-0.00057508,0.00046048,0.00098224,0.00082236,0.00025163,-0.00030014,-0.0005273,-0.00039861,-9.0916e-05,0.0001701,0.00025394},
		{-0.00022461,0.00034449,0.00021293,-0.00014522,-0.00054608,-0.00068896,-0.00036504,0.00035627,0.0010726,0.0012387,0.00054754,-0.00075395,-0.0018964,-0.0019952,-0.00070833,0.0013917,0.0030012,0.0028779,0.00075629,-0.0022607,-0.0042601,-0.0037162,-0.0006211,0.0032714,0.0054344,0.0042794,0.00027852,-0.0041933,-0.0062315,-0.0044134,0.000221,0.0047984,0.0064154,0.0040444,-0.00073017,-0.0049017,-0.0059051,-0.0032902,0.0011084,0.0044874,0.0048839,0.0023738,-0.0012504,-0.0036759,-0.0036252,-0.0014844,0.0011659,0.0026996,0.0024093,0.00080828,-0.00092795,-0.0017755,-0.0014354,-0.00036954,0.00064698,0.0010482,0.00076437,0.00013404,-0.00039507,-0.00055579,-0.000364,-3.1474e-05,0.00021397,0.00026419},
		{-0.00020583,0.00032758,0.00015566,-0.00021703,-0.00057969,-0.00064669,-0.0002457,0.00049277,0.0011292,0.0011434,0.00032363,-0.00098728,-0.0019684,-0.0018137,-0.00033187,0.0017465,0.0030816,0.0025635,0.0001878,-0.0027535,-0.0043327,-0.0032461,0.00014701,0.0038687,0.0054735,0.0036566,-0.00065935,-0.0048561,-0.0061864,-0.0036581,0.0012369,0.0054452,0.0062865,0.0032426,-0.0017344,-0.0054644,-0.0057161,-0.0025101,0.001978,0.0049213,0.004675,0.0016927,-0.0019333,-0.0039723,-0.0034157,-0.00096712,0.0016468,0.0028763,0.0022413,0.00044746,-0.0012364,-0.0018714,-0.0013141,-0.00014651,0.00082073,0.0010895,0.00068489,8.792e-06,-0.00048329,-0.00057104,-0.00031893,3.0903e-05,0.00025438,0.00026771},
		{-0.00018119,0.00030361,9.431e-05,-0.00028359,-0.00060343,-0.00058973,-0.00012113,0.00061816,0.0011583,0.0010257,9.1195e-05,-0.0011964,-0.0019975,-0.00159,5.5572e-05,0.0020636,0.0030874,0.0021969,-0.00038683,-0.0031775,-0.0042895,-0.0027001,0.00091632,0.0043668,0.005351,0.0029339,-0.0015785,-0.0053962,-0.0059806,-0.0028087,0.0022193,0.0059474,0.0060011,0.0023376,-0.0026796,-0.0059031,-0.005394,-0.0016573,0.0028062,0.0052399,0.0043429,0.00096449,-0.002585,-0.0041778,-0.0031228,-0.00041533,0.0021039,0.0029883,0.0020059,6.8202e-05,-0.0015207,-0.0019163,-0.00115,8.4256e-05,0.00098029,0.0011038,0.00058492,-0.00011817,-0.00056326,-0.00057063,-0.0002642,9.495e-05,0.00028918,0.00026439},
		{-0.0001506,0.00027264,3.1977e-05,-0.00034228,-0.00061112,-0.00051907,8.1971e-06,0.00072864,0.0011617,0.0008815,-0.0001407,-0.0013788,-0.0019792,-0.001327,0.00043684,0.0023306,0.0030285,0.0017734,-0.00094286,-0.0035266,-0.0041544,-0.0020838,0.0016559,0.0047841,0.0051121,0.0021406,-0.0024649,-0.0058084,-0.0056378,-0.0018699,0.0031764,0.0063288,0.0055617,0.0013695,-0.0035926,-0.006188,-0.0049208,-0.00074385,0.003586,0.0054278,0.0038909,0.00019752,-0.0031786,-0.004273,-0.0027325,0.00016493,0.0025143,0.0030261,0.0017188,-0.00032092,-0.0017709,-0.0019132,-0.00095333,0.00032627,0.0011156,0.0010909,0.00046588,-0.00024844,-0.00062999,-0.0005558,-0.00019953,0.00015849,0.00031844,0.00025443},
		{-0.00011564,0.00023636,-3.1669e-05,-0.0003958,-0.00060747,-0.00043711,0.00013493,0.00082096,0.0011401,0.00071844,-0.00037258,-0.0015261,-0.001918,-0.0010344,0.00081328,0.0025443,0.0028922,0.0013089,-0.0014948,-0.0037964,-0.0039119,-0.0014186,0.0023695,0.0050663,0.00474,0.0012809,-0.0033035,-0.0060772,-0.0051424,-0.00089301,0.0040548,0.0065581,0.0049831,0.00034552,-0.0044169,-0.0063285,-0.0043119,0.00019273,0.0042862,0.0054931,0.0033265,-0.00058482,-0.0036998,-0.0042711,-0.0022706,0.00074669,0.0028637,0.0029794,0.0013701,-0.00071504,-0.0019817,-0.0018649,-0.00072487,0.00056135,0.0012301,0.0010448,0.00033195,-0.00037611,-0.00068287,-0.00052618,-0.00012804,0.0002195,0.00033994,0.00023733},
		{-7.5681e-05,0.00019459,-9.3664e-05,-0.00043913,-0.00059039,-0.00034599,0.0002587,0.00089621,0.0010911,0.00053796,-0.00059426,-0.0016399,-0.0018075,-0.00071992,0.0011657,0.002695,0.002683,0.00081028,-0.0020029,-0.0039627,-0.0035754,-0.00071311,0.0030297,0.0052394,0.0042416,0.00038413,-0.0040495,-0.0061954,-0.0045049,0.00012189,0.0048266,0.0065833,0.0042693,-0.00069295,-0.0051241,-0.0062869,-0.0035718,0.0011486,0.0048628,0.0053804,0.0026487,-0.0013629,-0.0041238,-0.0041331,-0.0017286,0.0013227,0.0031355,0.0028445,0.0009803,-0.0010948,-0.0021358,-0.0017541,-0.00047136,0.000784,0.0013055,0.00096971,0.00018179,-0.00049532,-0.00071441,-0.00047905,-5.0917e-05,0.00027645,0.0003517,0.00021179},
		{-3.2256e-05,0.0001495,-0.00015451,-0.00047341,-0.00055912,-0.00024727,0.00037695,0.00095102,0.0010172,0.00034475,-0.00079971,-0.0017136,-0.0016543,-0.00038531,0.001491,0.002776,0.0024085,0.0002911,-0.0024522,-0.0040224,-0.0031309,9.867e-06,0.0035862,0.0052386,0.0036174,-0.00052379,-0.0046685,-0.0061061,-0.0037293,0.001139,0.0054251,0.0063906,0.0033821,-0.0017011,-0.0056341,-0.0060021,-0.0026988,0.0020385,0.0052389,0.0050521,0.0018724,-0.0020751,-0.0043617,-0.0038106,-0.0011178,0.0018273,0.003257,0.0025764,0.00054389,-0.0014136,-0.002184,-0.0015555,-0.00019374,0.00096745,0.0013118,0.0008418,2.625e-05,-0.00058614,-0.00070859,-0.00040667,2.8548e-05,0.00031684,0.00034292,0.00017488},
		{1.2643e-05,0.0001005,-0.00021134,-0.00049561,-0.00051589,-0.00014364,0.00048604,0.00098325,0.00091969,0.00014834,-0.00098842,-0.0017473,-0.0014649,-4.5747e-05,0.0017739,0.0027889,0.0020796,-0.00023488,-0.0028465,-0.0039849,-0.002612,0.00073036,0.0040558,0.0051169,0.0029101,-0.0014011,-0.005165,-0.0058679,-0.0028554,0.0021006,0.0058753,0.0060406,0.002439,-0.0026504,-0.0059972,-0.005566,-0.001777,0.0028736,0.0054764,0.0046062,0.0010734,-0.0027241,-0.0044857,-0.0034009,-0.00048297,0.0022792,0.0032964,0.0022458,0.00010197,-0.0016918,-0.002175,-0.0013291,7.8566e-05,0.0011176,0.0012862,0.00069744,-0.00012683,-0.00066042,-0.0006838,-0.00032641,0.00010475,0.00034835,0.00032615,0.0001344},
		{5.4896e-05,5.0036e-05,-0.00026299,-0.00050803,-0.00046071,-3.6264e-05,0.00058544,0.0009937,0.0008034,-5.4087e-05,-0.0011499,-0.0017439,-0.0012413,0.0002921,0.0020204,0.0027391,0.0016948,-0.00074652,-0.0031598,-0.0038514,-0.0020399,0.0014234,0.0044283,0.0048608,0.002139,-0.0022399,-0.0055244,-0.0054826,-0.0019328,0.0030143,0.0061778,0.0055347,0.0014378,-0.0035124,-0.0061919,-0.0050074,-0.00082158,0.003614,0.0055744,0.004044,0.00025093,-0.0032865,-0.0044902,-0.0029188,0.00013097,0.0026569,0.0032496,0.0018721,-0.0003271,-0.0019174,-0.0021078,-0.0010689,0.00034189,0.001237,0.0012286,0.00054047,-0.00026951,-0.00071408,-0.00064317,-0.00024007,0.00017526,0.00036918,0.00030269,9.2991e-05},
		{9.5142e-05,-2.0951e-06,-0.00030864,-0.00050947,-0.00039673,7.1378e-05,0.00067018,0.00098317,0.00066685,-0.00025559,-0.0012899,-0.001697,-0.00099085,0.00062633,0.0022183,0.0026272,0.0012803,-0.0012443,-0.0034038,-0.0036349,-0.0014269,0.0020758,0.0046742,0.0044897,0.0013194,-0.0030055,-0.005751,-0.0049672,-0.00096513,0.0038224,0.006338,0.0049026,0.00042167,-0.0042774,-0.0062537,-0.0043349,0.00013286,0.0042513,0.0055301,0.0034004,-0.00054786,-0.0037573,-0.004387,-0.0023713,0.00074663,0.0029621,0.0031225,0.0014593,-0.00073181,-0.002094,-0.0019937,-0.00079281,0.00058699,0.0013223,0.0011451,0.0003747,-0.00040094,-0.000748,-0.0005878,-0.00015174,0.00023818,0.00038082,0.00027175,5.0967e-05},
		{0.00013093,-5.3871e-05,-0.00034861,-0.00049904,-0.00032295,0.00017728,0.00073861,0.00094905,0.00051755,-0.0004489,-0.0013961,-0.0016104,-0.0007151,0.0009423,0.002357,0.002446,0.00084135,-0.0017013,-0.0035628,-0.0033207,-0.00078223,0.0026708,0.0048186,0.0040175,0.00048537,-0.0036998,-0.0058311,-0.0043375,6.6997e-06,0.0045322,0.0063175,0.0041712,-0.00058556,-0.0049242,-0.0061307,-0.0035579,0.0010684,0.0047688,0.0053391,0.0026796,-0.0013233,-0.004127,-0.0041645,-0.0017712,0.0013215,0.0031815,0.002918,0.0010243,-0.0011136,-0.0022057,-0.0018311,-0.00050488,0.00080944,0.0013687,0.0010302,0.000206,-0.00051854,-0.00076331,-0.00051914,-6.244e-05,0.00029358,0.00038166,0.0002353,9.1385e-06},
		{0.00016181,-0.00010424,-0.00037966,-0.00047764,-0.00024336,0.00027884,0.00079253,0.00089343,0.00035629,-0.00063034,-0.0014711,-0.0014904,-0.00042809,0.0012366,0.0024495,0.0022175,0.00037099,-0.0021192,-0.0036361,-0.0029346,-0.00011654,0.0032063,0.0048437,0.0034569,-0.00036192,-0.0042992,-0.0057587,-0.0036179,0.00096537,0.0051224,0.0061503,0.0033412,-0.0015544,-0.0054392,-0.0058734,-0.0027013,0.0019514,0.0051484,0.0050258,0.0019125,-0.0020551,-0.0043696,-0.0038533,-0.0011438,0.0018426,0.0033164,0.0026427,0.00056589,-0.001449,-0.002255,-0.001626,-0.00021362,0.0010062,0.0013797,0.00089517,3.8012e-05,-0.00061745,-0.00075777,-0.00044103,2.4223e-05,0.00033879,0.00037307,0.00019416,-3.1208e-05},
		{0.00018686,-0.00015186,-0.00040326,-0.00044663,-0.00015786,0.00037488,0.00082679,0.00081736,0.0001893,-0.00079995,-0.0015118,-0.0013331,-0.00012687,0.0014983,0.0024746,0.0019328,-9.2157e-05,-0.0024876,-0.0036279,-0.0024779,0.00054022,0.0036584,0.0047472,0.0028178,-0.0011872,-0.0047724,-0.0055594,-0.0028044,0.0019017,0.0055669,0.0058325,0.0024242,-0.0024847,-0.0057977,-0.0054626,-0.0017909,0.0027869,0.0053996,0.0045878,0.0011017,-0.0027018,-0.0044994,-0.0034335,-0.00050421,0.0023064,0.0033605,0.0023071,0.00011883,-0.0017421,-0.0022526,-0.001386,7.8977e-05,0.0011689,0.0013531,0.00074122,-0.0001275,-0.00069795,-0.0007308,-0.00035397,0.00010759,0.00037333,0.00035525,0.00014999,-6.8804e-05},
		{0.00020665,-0.00019685,-0.00041716,-0.00040487,-6.8765e-05,0.00046035,0.00084322,0.00072424,1.4593e-05,-0.0009486,-0.0015187,-0.0011486,0.00017002,0.0017284,0.0024494,0.0016053,-0.00056104,-0.0027901,-0.0035311,-0.0019716,0.0011831,0.0040113,0.0045385,0.0021084,-0.0019791,-0.0051467,-0.0052175,-0.0019317,0.0027662,0.0058731,0.0053644,0.00147,-0.0033395,-0.006011,-0.0049196,-0.00085885,0.0035314,0.0055098,0.0040338,0.0002824,-0.0032765,-0.0045117,-0.0029439,0.00013983,0.0027013,0.0033147,0.0019262,-0.00032958,-0.0019793,-0.0021855,-0.0011155,0.00035428,0.0012954,0.0012923,0.00057457,-0.00028106,-0.00075636,-0.00068838,-0.00026183,0.00018431,0.00039702,0.00032862,0.00010449,-0.00010378},
		{0.00022022,-0.00023699,-0.00042261,-0.00035541,2.0762e-05,0.00053637,0.00084012,0.00061585,-0.0001575,-0.0010755,-0.0014921,-0.00093448,0.00046407,0.0019115,0.0023616,0.0012445,-0.0010088,-0.0030267,-0.0033435,-0.0014147,0.0017928,0.0042623,0.0042225,0.0013622,-0.002704,-0.0053739,-0.0047518,-0.001019,0.0035515,0.0060482,0.0047825,0.00048721,-0.0040933,-0.0060774,-0.0042697,8.7973e-05,0.0041635,0.0054638,0.0033961,-0.00053665,-0.0037534,-0.004408,-0.0023946,0.0007555,0.0030157,0.0031869,0.0014967,-0.00075539,-0.0021617,-0.0020655,-0.00082067,0.00061425,0.0013851,0.0012031,0.00039726,-0.00042363,-0.000794,-0.00062889,-0.00016513,0.00025427,0.00040905,0.00029503,5.7779e-05,-0.00013437},
		{0.00022713,-0.00027194,-0.00041802,-0.00029735,0.00011002,0.00060033,0.00081909,0.00049192,-0.00032451,-0.0011767,-0.0014272,-0.00070277,0.00074656,0.0020537,0.0022222,0.00085248,-0.0014307,-0.0031879,-0.003086,-0.00083463,0.0023484,0.0044284,0.0038023,0.00057737,-0.003371,-0.0054694,-0.0041756,-9.3206e-05,0.0042605,0.0060567,0.0040573,-0.00048161,-0.0047402,-0.0059745,-0.0035051,0.0010161,0.0046879,0.0052921,0.0026765,-0.0013156,-0.0041314,-0.0041947,-0.0017902,0.0013391,0.0032399,0.0029735,0.0010419,-0.0011516,-0.0022791,-0.0018949,-0.00051927,0.0008499,0.001435,0.0010803,0.0002167,-0.00055001,-0.00081003,-0.00055391,-6.844e-05,0.00031383,0.00041112,0.00025531,1.1309e-05,-0.00015966},
		{0.00022867,-0.000301,-0.0004052,-0.00023289,0.00019804,0.00065175,0.0007783,0.00035752,-0.00048699,-0.0012508,-0.0013369,-0.0004551,0.0010059,0.0021471,0.0020317,0.00044277,-0.0018161,-0.0032802,-0.002747,-0.00023685,0.0028519,0.0044707,0.0032965,-0.00020509,-0.0039445,-0.0054388,-0.003497,0.0008174,0.0048299,0.0058991,0.0032729,-0.0014476,-0.0052555,-0.0057338,-0.0026766,0.0018897,0.0050844,0.0049891,0.0019013,-0.0020475,-0.0043809,-0.0038799,-0.0011571,0.0018791,0.0033823,0.0026985,0.00057046,-0.0015004,-0.0023364,-0.0016796,-0.00021041,0.0010568,0.0014449,0.00093907,3.3453e-05,-0.00065647,-0.00080402,-0.00046925,2.6796e-05,0.00036419,0.00040086,0.00021052,-3.3136e-05,-0.00017969},
		{0.0002235,-0.00032326,-0.00038251,-0.00016318,0.00027969,0.00068679,0.00072213,0.00021606,-0.00063352,-0.0012972,-0.0012087,-0.00019796,0.0012501,0.0021886,0.0017941,2.5676e-05,-0.0021568,-0.0032842,-0.0023548,0.00036538,0.0032801,0.0044044,0.002711,-0.00097612,-0.0044177,-0.0052663,-0.0027517,0.0017076,0.0052868,0.005616,0.0024096,-0.0023538,-0.0056238,-0.0053582,-0.0017919,0.002711,0.0053442,0.0045424,0.0010966,-0.0027085,-0.0045173,-0.0034577,-0.00049254,0.0023568,0.0034274,0.0023497,9.9907e-05,-0.0018008,-0.0023273,-0.0014257,9.1996e-05,0.0012278,0.0014196,0.00077132,-0.00014151,-0.00074221,-0.00077552,-0.00037387,0.00011812,0.00040152,0.0003813,0.00016118,-7.4849e-05,-0.00019404},
		{0.00021248,-0.00033925,-0.00035254,-9.1144e-05,0.0003555,0.00070799,0.00065011,7.2285e-05,-0.00076845,-0.0013142,-0.0010549,6.3495e-05,0.0014586,0.0021792,0.0015161,-0.0003887,-0.0024464,-0.003217,-0.0019052,0.00095672,0.0036285,0.0042319,0.0020752,-0.0017239,-0.0047809,-0.0049633,-0.0019376,0.0025449,0.005602,0.0051865,0.0014889,-0.0031901,-0.0058497,-0.0048296,-0.0008741,0.003455,0.005446,0.0040168,0.00027335,-0.0032895,-0.0045395,-0.0029592,0.00016026,0.0027649,0.0033818,0.0019495,-0.00036705,-0.0020581,-0.0022608,-0.0011372,0.00039018,0.0013633,0.0013541,0.00059194,-0.00031102,-0.00080691,-0.00072669,-0.00027191,0.00020266,0.00042691,0.00035187,0.00011062,-0.00011316,-0.00020285},
		{0.00019694,-0.00034677,-0.00031481,-1.6841e-05,0.00042341,0.00071246,0.00056163,-7.5769e-05,-0.00088492,-0.0012998,-0.00088024,0.00032036,0.001635,0.0021174,0.0012021,-0.00079482,-0.0026783,-0.0030747,-0.0014112,0.0015248,0.003887,0.0039592,0.001383,-0.0024203,-0.0050179,-0.0045487,-0.0010775,0.0032971,0.00577,0.0046264,0.00053452,-0.0039255,-0.0059249,-0.0042005,6.0868e-05,0.0041038,0.0054211,0.003379,-0.00053961,-0.0037718,-0.0044437,-0.0024014,0.00079358,0.0030836,0.0032455,0.0015074,-0.00080292,-0.0022441,-0.0021315,-0.00083301,0.00066455,0.0014551,0.0012534,0.00040247,-0.00046116,-0.00084625,-0.00066185,-0.00016841,0.00027723,0.00043967,0.00031463,5.8961e-05,-0.00014639,-0.00020556},
		{0.00017662,-0.00034687,-0.00026947,5.8266e-05,0.00048008,0.0006997,0.00046213,-0.00022154,-0.00098061,-0.001259,-0.0006853,0.0005724,0.0017745,0.0020112,0.00086109,-0.0011768,-0.0028376,-0.0028506,-0.00088438,0.0020437,0.0040489,0.0035953,0.00066905,-0.0030587,-0.0051343,-0.0040193,-0.00019943,0.0039835,0.0057972,0.0039818,-0.00041196,-0.0045645,-0.0058448,-0.0034635,0.00097734,0.0046192,0.0052523,0.0026607,-0.0013258,-0.004151,-0.0042158,-0.0017884,0.0013886,0.0033185,0.0030295,0.0010358,-0.001216,-0.0023669,-0.0019509,-0.00051135,0.00090911,0.0015054,0.0011221,0.00020662,-0.00059574,-0.00085925,-0.00057995,-6.2393e-05,0.00034159,0.00044062,0.000271,7.628e-06,-0.00017422,-0.0002031},
		{0.00015262,-0.00034007,-0.0002194,0.00013107,0.00052781,0.00067344,0.00035245,-0.00036169,-0.0010547,-0.0011859,-0.000476,0.00080862,0.0018677,0.0018525,0.0005049,-0.0015316,-0.0029374,-0.0025681,-0.00033711,0.0025194,0.0041143,0.0031409,-6.6189e-05,-0.003608,-0.0051107,-0.0033928,0.00067386,0.0045544,0.0056761,0.0032048,-0.001331,-0.0050761,-0.0056214,-0.0026593,0.0018498,0.005019,0.0049531,0.0018914,-0.0020676,-0.004422,-0.0038923,-0.0011438,0.0019467,0.003464,0.0027391,0.00054395,-0.0015825,-0.0024194,-0.0017196,-0.00018609,0.0011285,0.0015136,0.00096555,1.2761e-05,-0.0007091,-0.00084952,-0.00048705,4.0904e-05,0.00039518,0.00042854,0.00022054,-4.1293e-05,-0.00019623,-0.00019484},
		{0.00012536,-0.00032519,-0.0001638,0.00020205,0.00056428,0.00063127,0.00023491,-0.00049221,-0.0011036,-0.0010874,-0.00025231,0.001026,0.0019181,0.001657,0.00013241,-0.0018486,-0.0029617,-0.0022234,0.00020389,0.0029246,0.0040745,0.0026223,-0.00078462,-0.0040693,-0.0049885,-0.0026951,0.0015166,0.0050041,0.0054213,0.0023834,-0.0022304,-0.0054518,-0.0052518,-0.0017795,0.0026648,0.0052835,0.0045288,0.0010758,-0.0027376,-0.0045626,-0.0034775,-0.00046305,0.0024343,0.0035066,0.0023742,5.9112e-05,-0.0018962,-0.002405,-0.0014462,0.00013908,0.0013072,0.0014834,0.00078761,-0.00017525,-0.00080032,-0.00081795,-0.00038194,0.00013898,0.00043395,0.00040575,0.00016667,-8.72e-05,-0.00021145,-0.00018149},
		{9.6346e-05,-0.00030371,-0.00010467,0.00026718,0.0005864,0.00057572,0.00011128,-0.00061239,-0.0011281,-0.00096399,-2.5629e-05,0.0012171,0.0019234,0.0014248,-0.00023535,-0.0021271,-0.0029222,-0.0018236,0.00074627,0.0032629,0.0039402,0.002035,-0.0014871,-0.0044256,-0.004724,-0.0019341,0.0023241,0.005327,0.0050293,0.0015034,-0.0030423,-0.0056834,-0.0047489,-0.00087036,0.003408,0.005408,0.0039905,0.00024733,-0.0033294,-0.0045782,-0.0029719,0.00020381,0.0028529,0.0034566,0.0019588,-0.00042595,-0.0021531,-0.0023277,-0.0011464,0.00044242,0.0014451,0.0014086,0.00059349,-0.00035392,-0.00086322,-0.00076356,-0.00027193,0.00023181,0.00046057,0.00037209,0.00010992,-0.00012845,-0.00021958,-0.00016371},
		{6.5453e-05,-0.00027553,-4.4043e-05,0.00032659,0.0005974,0.00050788,-1.2362e-05,-0.00071861,-0.0011259,-0.00082117,0.00019751,0.0013828,0.0018901,0.0011542,-0.0006037,-0.0023455,-0.0028089,-0.0013936,0.0012684,0.0035118,0.0037093,0.0014034,-0.0021429,-0.0046779,-0.0043429,-0.0011287,0.0030595,0.0055018,0.0045106,0.0005848,-0.0037676,-0.0057808,-0.0041312,4.0408e-05,0.0040456,0.0053866,0.0033618,-0.00056353,-0.0038113,-0.0044703,-0.0023976,0.0008497,0.0031839,0.0033138,0.0014958,-0.00088613,-0.0023478,-0.0021925,-0.00082033,0.00073498,0.0015419,0.0012988,0.00038755,-0.00051536,-0.00090293,-0.00069037,-0.00015593,0.00031186,0.00047282,0.00032952,5.2569e-05,-0.00016436,-0.00022236,-0.00014179},
		{3.4716e-05,-0.00024135,1.7958e-05,0.00037933,0.00059375,0.00042827,-0.00013715,-0.00080782,-0.001098,-0.00065852,0.00041924,0.0015154,0.0018095,0.00086054,-0.00094577,-0.0025112,-0.0026275,-0.00092692,0.0017535,0.0036856,0.0033887,0.00075026,-0.0027459,-0.0047939,-0.0038754,-0.00029638,0.0037233,0.0055519,0.0038863,-0.00033242,-0.0044061,-0.0057156,-0.0034252,0.00094793,0.0045693,0.0052206,0.0026409,-0.0013584,-0.0041993,-0.0042505,-0.0017618,0.0014722,0.0034147,0.0030826,0.0010121,-0.0013104,-0.0024674,-0.0019968,-0.00047987,0.00099768,0.0015902,0.0011582,0.00017749,-0.00065677,-0.00091414,-0.00059912,-4.2967e-05,0.00038089,0.00047102,0.00027961,-3.4641e-06,-0.00019422,-0.00021854,-0.0001177}

};

//float fftIn[NChirp][ADC_BUF_LEN];
float fftOut[NChirp][ADC_BUF_LEN];
float fft2In[ADC_BUF_LEN/2][2*NChirp];

arm_rfft_fast_instance_f32 fftHandler;
arm_cfft_instance_f32 TwofftHandler;

/* USER CODE END PV */

void SystemClock_Config(void);
static void MX_GPIO_Init(void);
static void MX_DMA_Init(void);
static void MX_ADC1_Init(void);
static void MX_USART2_UART_Init(void);

/* USER CODE BEGIN 0 */

uint8_t callback_state = 0;
uint8_t uartfree = 1;

float complexABS(float real, float compl) {
	return sqrtf(real*real + compl*compl);
}

void DoFFT(){

	for(int d =0; d<NChirp; d++){

		arm_rfft_fast_f32(&fftHandler, &fftIn[d], &fftOut[d], 0);

	}

	int n = 0;
	int j = -2;

	for(int m = 0; m < ADC_BUF_LEN/2; m++){
		j = j + 2;

		for( int k = 0; k < NChirp; k++){
			for(int i = 0; i<2; i++,j++,n++){
				fft2In[m][n] = fftOut[k][j];
			}
			j = j-2;
		}
		n = 0;
		//arm_cfft_f32(&arm_cfft_sR_f32_len64, &fft2In[m], 0, 1);
	}

	for(int e = 0; e<ADC_BUF_LEN/2; e++){
	arm_cfft_f32(&arm_cfft_sR_f32_len64, &fft2In[e], 0, 1);
	}

	float freqs[ADC_BUF_LEN/2][NChirp];
	int freqvalues = 0;
	int chirp = 0;
	int offset = 0;
	int c = 0;
	int p = 0;
	int i = 0;
	int m = 0;
	float outarray[ADC_BUF_LEN/2][NChirp];
	char temp_buf[200];

	for( m = 0; m<ADC_BUF_LEN/2; m++){

		for ( i = 0; i < 2*NChirp; i = i+2) {
			freqs[chirp][freqvalues] = (20*log10f(complexABS(fft2In[m][i], fft2In[m][i+1]))) - offset;
			if(freqs[chirp][freqvalues] < 0) freqs[chirp][freqvalues] = 0;

			freqs[chirp][0] = 0;

			outarray[p][c] = freqs[chirp][freqvalues];
			freqvalues++;
			c++;
		}
		freqvalues = 0;
		c = 0;
		i = 0;
		chirp++;
		p++;
	}

	float max = 0;
	float max1 = 0;
	float max2 = 0;

	int maxrow = -1;
	int maxcol = -1;

	int max1row = -1;
	int max1col = -1;

	int max2row = -1;
	int max2col = -1;

	float velocity = 0.00f;
	float range = 0.00f;

	for(int m=0; m<ADC_BUF_LEN/2; m++){
		for(int n=0; n<NChirp; n++){
			if(outarray[m][n]> max){

				max2 = max1;
				max1 = max;
				max = outarray[m][n];
				maxrow = m;
				maxcol = n;
			}

			else if(outarray[m][n]> max1){

				max2 = max1;
				max1 = outarray[m][n];
				max1row = m;
				max1col = n;
			}

			else if(outarray[m][n]> max2){

				max2 = outarray[m][n];
				max2row = m;
				max2col = n;
			}

		}
	}

	range = 0.375 * maxrow;

	if(maxcol<=7){
		 velocity = maxcol * 9.15 * 2;
	}
	else{
//		 velocity = (-1 *(16 - ((maxcol + 1) * 0.5))) * 9.15;
		 velocity = (-1 *(16 - maxcol)) * 9.15 * 2;
	}

	snprintf(temp_buf, sizeof(temp_buf), "%f %f %d %d\r\n", range, velocity, maxcol, maxrow);
	HAL_UART_Transmit(&huart2, (uint8_t*)temp_buf, strlen(temp_buf), HAL_MAX_DELAY);

	HAL_GPIO_WritePin(LD2_GPIO_Port, LD2_Pin, GPIO_PIN_RESET);

}
/* USER CODE END 0 */

int main(void)
{

	/* MCU Configuration--------------------------------------------------------*/

	/* Reset of all peripherals, Initializes the Flash interface and the Systick. */
	HAL_Init();

	/* Configure the system clock */
	SystemClock_Config();

	/* Initialize all configured peripherals */
	MX_GPIO_Init();
	MX_DMA_Init();
	MX_ADC1_Init();
	MX_USART2_UART_Init();
	/* USER CODE BEGIN 2 */

	arm_rfft_fast_init_f32(&fftHandler, 64);

	//HAL_ADC_Start_DMA(&hadc1, (uint32_t*)adc_buf, ADC_BUF_LEN);
	DoFFT();
	/* USER CODE END 2 */

	/* Infinite loop */
	while (1)
	{

		/* USER CODE BEGIN 3 */

//		if(callback_state == 1){
//
//					for(int Ci = 0; Ci < NChirp; Ci++){
//						int fft_in_ptr = 0;
//						for( int Si = 0; Si < ADC_BUF_LEN; Si++){
//
//							fftIn[Ci][fft_in_ptr] = (float32_t) adc_buf[Si];
//							fft_in_ptr++;
//						}
//						//arm_rfft_fast_f32(&fftHandler, &fftIn[Ci], &fftOut[Ci], 0);
//					}

//					HAL_GPIO_WritePin(LD2_GPIO_Port, LD2_Pin, GPIO_PIN_RESET);
//		}
	}
	/* USER CODE END 3 */
}

void SystemClock_Config(void)
{
	RCC_OscInitTypeDef RCC_OscInitStruct = {0};
	RCC_ClkInitTypeDef RCC_ClkInitStruct = {0};

	/** Configure the main internal regulator output voltage
	 */
	if (HAL_PWREx_ControlVoltageScaling(PWR_REGULATOR_VOLTAGE_SCALE1) != HAL_OK)
	{
		Error_Handler();
	}
	/** Initializes the RCC Oscillators according to the specified parameters
	 * in the RCC_OscInitTypeDef structure.
	 */
	RCC_OscInitStruct.OscillatorType = RCC_OSCILLATORTYPE_HSI;
	RCC_OscInitStruct.HSIState = RCC_HSI_ON;
	RCC_OscInitStruct.HSICalibrationValue = RCC_HSICALIBRATION_DEFAULT;
	RCC_OscInitStruct.PLL.PLLState = RCC_PLL_ON;
	RCC_OscInitStruct.PLL.PLLSource = RCC_PLLSOURCE_HSI;
	RCC_OscInitStruct.PLL.PLLM = 1;
	RCC_OscInitStruct.PLL.PLLN = 10;
	RCC_OscInitStruct.PLL.PLLP = RCC_PLLP_DIV7;
	RCC_OscInitStruct.PLL.PLLQ = RCC_PLLQ_DIV2;
	RCC_OscInitStruct.PLL.PLLR = RCC_PLLR_DIV2;
	if (HAL_RCC_OscConfig(&RCC_OscInitStruct) != HAL_OK)
	{
		Error_Handler();
	}
	/** Initializes the CPU, AHB and APB buses clocks
	 */
	RCC_ClkInitStruct.ClockType = RCC_CLOCKTYPE_HCLK|RCC_CLOCKTYPE_SYSCLK
			|RCC_CLOCKTYPE_PCLK1|RCC_CLOCKTYPE_PCLK2;
	RCC_ClkInitStruct.SYSCLKSource = RCC_SYSCLKSOURCE_PLLCLK;
	RCC_ClkInitStruct.AHBCLKDivider = RCC_SYSCLK_DIV1;
	RCC_ClkInitStruct.APB1CLKDivider = RCC_HCLK_DIV1;
	RCC_ClkInitStruct.APB2CLKDivider = RCC_HCLK_DIV1;

	if (HAL_RCC_ClockConfig(&RCC_ClkInitStruct, FLASH_LATENCY_4) != HAL_OK)
	{
		Error_Handler();
	}
}

static void MX_ADC1_Init(void)
{

	ADC_MultiModeTypeDef multimode = {0};
	ADC_ChannelConfTypeDef sConfig = {0};

	/** Common config
	 */
	hadc1.Instance = ADC1;
	hadc1.Init.ClockPrescaler = ADC_CLOCK_ASYNC_DIV1;
	hadc1.Init.Resolution = ADC_RESOLUTION_12B;
	hadc1.Init.DataAlign = ADC_DATAALIGN_RIGHT;
	hadc1.Init.ScanConvMode = ADC_SCAN_DISABLE;
	hadc1.Init.EOCSelection = ADC_EOC_SINGLE_CONV;
	hadc1.Init.LowPowerAutoWait = DISABLE;
	hadc1.Init.ContinuousConvMode = ENABLE;
	hadc1.Init.NbrOfConversion = 1;
	hadc1.Init.DiscontinuousConvMode = DISABLE;
	hadc1.Init.ExternalTrigConv = ADC_SOFTWARE_START;
	hadc1.Init.ExternalTrigConvEdge = ADC_EXTERNALTRIGCONVEDGE_NONE;
	hadc1.Init.DMAContinuousRequests = ENABLE;
	hadc1.Init.Overrun = ADC_OVR_DATA_PRESERVED;
	hadc1.Init.OversamplingMode = DISABLE;
	if (HAL_ADC_Init(&hadc1) != HAL_OK)
	{
		Error_Handler();
	}
	/** Configure the ADC multi-mode
	 */
	multimode.Mode = ADC_MODE_INDEPENDENT;
	if (HAL_ADCEx_MultiModeConfigChannel(&hadc1, &multimode) != HAL_OK)
	{
		Error_Handler();
	}
	/** Configure Regular Channel
	 */
	sConfig.Channel = ADC_CHANNEL_5;
	sConfig.Rank = ADC_REGULAR_RANK_1;
	sConfig.SamplingTime = ADC_SAMPLETIME_2CYCLES_5;
	sConfig.SingleDiff = ADC_SINGLE_ENDED;
	sConfig.OffsetNumber = ADC_OFFSET_NONE;
	sConfig.Offset = 0;
	if (HAL_ADC_ConfigChannel(&hadc1, &sConfig) != HAL_OK)
	{
		Error_Handler();
	}

}

static void MX_USART2_UART_Init(void)
{

	huart2.Instance = USART2;
	huart2.Init.BaudRate = 115200;
	huart2.Init.WordLength = UART_WORDLENGTH_8B;
	huart2.Init.StopBits = UART_STOPBITS_1;
	huart2.Init.Parity = UART_PARITY_NONE;
	huart2.Init.Mode = UART_MODE_TX_RX;
	huart2.Init.HwFlowCtl = UART_HWCONTROL_NONE;
	huart2.Init.OverSampling = UART_OVERSAMPLING_16;
	huart2.Init.OneBitSampling = UART_ONE_BIT_SAMPLE_DISABLE;
	huart2.AdvancedInit.AdvFeatureInit = UART_ADVFEATURE_NO_INIT;
	if (HAL_UART_Init(&huart2) != HAL_OK)
	{
		Error_Handler();
	}

}

static void MX_DMA_Init(void)
{

	/* DMA controller clock enable */
	__HAL_RCC_DMA1_CLK_ENABLE();

	/* DMA interrupt init */
	/* DMA1_Channel1_IRQn interrupt configuration */
	HAL_NVIC_SetPriority(DMA1_Channel1_IRQn, 0, 0);
	HAL_NVIC_EnableIRQ(DMA1_Channel1_IRQn);

}

static void MX_GPIO_Init(void)
{
	GPIO_InitTypeDef GPIO_InitStruct = {0};

	/* GPIO Ports Clock Enable */
	__HAL_RCC_GPIOC_CLK_ENABLE();
	__HAL_RCC_GPIOH_CLK_ENABLE();
	__HAL_RCC_GPIOA_CLK_ENABLE();
	__HAL_RCC_GPIOB_CLK_ENABLE();

	/*Configure GPIO pin Output Level */
	HAL_GPIO_WritePin(LD2_GPIO_Port, LD2_Pin, GPIO_PIN_RESET);

	/*Configure GPIO pin : B1_Pin */
	GPIO_InitStruct.Pin = B1_Pin;
	GPIO_InitStruct.Mode = GPIO_MODE_IT_FALLING;
	GPIO_InitStruct.Pull = GPIO_NOPULL;
	HAL_GPIO_Init(B1_GPIO_Port, &GPIO_InitStruct);

	/*Configure GPIO pin : LD2_Pin */
	GPIO_InitStruct.Pin = LD2_Pin;
	GPIO_InitStruct.Mode = GPIO_MODE_OUTPUT_PP;
	GPIO_InitStruct.Pull = GPIO_NOPULL;
	GPIO_InitStruct.Speed = GPIO_SPEED_FREQ_LOW;
	HAL_GPIO_Init(LD2_GPIO_Port, &GPIO_InitStruct);

}

/* USER CODE BEGIN 4 */
void HAL_ADC_ConvHalfCpltCallback(ADC_HandleTypeDef* hadc) {

	//callback_state = 1;

	//	HAL_ADC_Stop_DMA(&hadc1);
	//
	//	int fft_in_ptr = 0;
	//
	//	if(callback_state == 1){
	//		for(int i =0; i<2048; i++){
	//
	//			fftBufIn[fft_in_ptr] = (float32_t) adc_buf[i];
	//			fft_in_ptr++;
	//		}
	//
	//		DoFFT();
	//	}
	//	NVIC_SystemReset();
}

void HAL_ADC_ConvCpltCallback(ADC_HandleTypeDef* hadc) {

	callback_state = 1;
	//HAL_ADC_Stop_DMA(&hadc1);

	//	int fft_in_ptr = 0;
	//
	//
	//
	//	if(callback_state == 2){
	//		for(int i =2048; i<4096; i++){
	//
	//			fftBufIn[i] = (float32_t) adc_buf[i];
	//			fft_in_ptr++;
	//		}
	//
	//		DoFFT();
	//	}

}
/* USER CODE END 4 */

void Error_Handler(void)
{
	__disable_irq();
	while (1)
	{
	}
}
